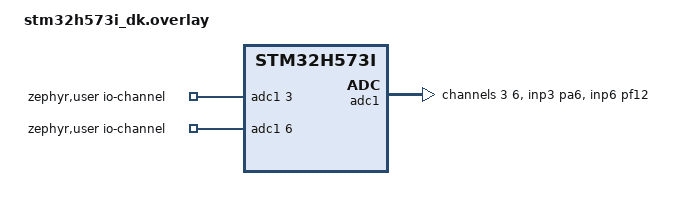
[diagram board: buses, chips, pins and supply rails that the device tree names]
/*
 * Copyright (c) 2023 STMicroelectronics
 * Copyright (c) Benjamin Björnsson <benjamin.bjornsson@gmail.com>
 *
 * SPDX-License-Identifier: Apache-2.0
 */

/ {
	zephyr,user {
		/* adjust channel number according to pinmux in board.dts */
		io-channels = <&adc1 3>, <&adc1 6>;
	};
};

&adc1 {
	dmas = <&gpdma1 0 0 (STM32_DMA_PERIPH_RX | STM32_DMA_MEM_16BITS | STM32_DMA_PERIPH_16BITS)>;
	dma-names = "gpdma";

	pinctrl-0 = <&adc1_inp3_pa6 &adc1_inp6_pf12>;
	#address-cells = <1>;
	#size-cells = <0>;

	channel@3 {
		reg = <3>;
		zephyr,gain = "ADC_GAIN_1";
		zephyr,reference = "ADC_REF_INTERNAL";
		zephyr,acquisition-time = <ADC_ACQ_TIME_DEFAULT>;
		zephyr,resolution = <12>;
	};

	channel@6 {
		reg = <6>;
		zephyr,gain = "ADC_GAIN_1";
		zephyr,reference = "ADC_REF_INTERNAL";
		zephyr,acquisition-time = <ADC_ACQ_TIME_DEFAULT>;
		zephyr,resolution = <12>;
	};
};

&gpdma1 {
	status = "okay";
};
